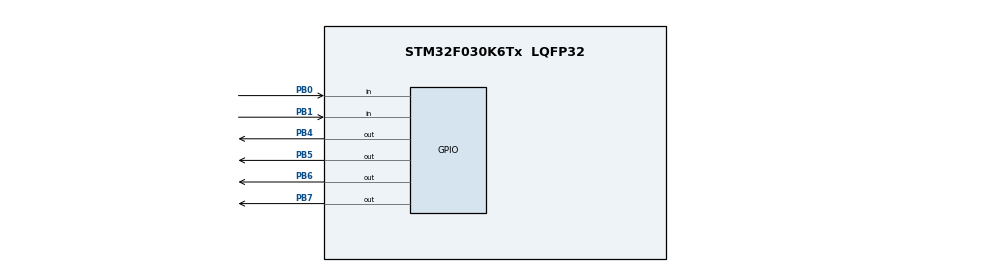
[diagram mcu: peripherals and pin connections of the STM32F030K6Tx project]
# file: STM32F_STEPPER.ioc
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Mcu.Family=STM32F0
Mcu.Name=STM32F030K6Tx
Mcu.Package=LQFP32
PB0.GPIO_PuPd=GPIO_PULLUP
PB0.Signal=GPIO_Input
PB1.GPIO_PuPd=GPIO_PULLUP
PB1.Signal=GPIO_Input
PB4.Signal=GPIO_Output
PB5.Signal=GPIO_Output
PB6.Signal=GPIO_Output
PB7.Signal=GPIO_Output
ProjectManager.HeapSize=0x200
ProjectManager.StackSize=0x400
ProjectManager.TargetToolchain=STM32CubeIDE
board=custom

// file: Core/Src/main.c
/* USER CODE BEGIN Header */
/**
 * 2022-05-14
 * Created by : bonusoid
 * Stepper Motor Control
  ******************************************************************************
  * @file           : main.c
  * @brief          : Main program body
  ******************************************************************************
  * @attention
  *
  * Copyright (c) 2022 STMicroelectronics.
  * All rights reserved.
  *
  * This software is licensed under terms that can be found in the LICENSE file
  * in the root directory of this software component.
  * If no LICENSE file comes with this software, it is provided AS-IS.
  *
  ******************************************************************************
  */
/* USER CODE END Header */
#include "main.h"

/* USER CODE BEGIN PD */
#define MOTIO	GPIOB //Stepper Motor GPIO Port
#define MOTP1	4	  //Stepper Motor Pin 1
#define BTNIO	GPIOB      //Button GPIO Port
#define BTNCW	GPIO_PIN_0 //Button for Clockwise
#define BTNCCW	GPIO_PIN_1 //Button for Counter-Clockwise
/* USER CODE END PD */

/* USER CODE BEGIN PV */
//STEP SEQUENCE
unsigned char stepcw[4] = {0b1010,0b1001,0b0101,0b0110};  //Clockwise
unsigned char stepccw[4] = {0b0101,0b1001,0b1010,0b0110}; //Counter-Clockwise
/* USER CODE END PV */

void SystemClock_Config(void);
static void MX_GPIO_Init(void);
/* USER CODE BEGIN PFP */
void setstep(unsigned char st); //Update rotor step
/* USER CODE END PFP */

int main(void)
{
  /* USER CODE BEGIN 1 */
  unsigned char sti; //Step increment
  /* USER CODE END 1 */

  /* MCU Configuration--------------------------------------------------------*/

  /* Reset of all peripherals, Initializes the Flash interface and the Systick. */
  HAL_Init();

  /* Configure the system clock */
  SystemClock_Config();

  /* Initialize all configured peripherals */
  MX_GPIO_Init();

  /* Infinite loop */
  while (1)
  {
	  if((HAL_GPIO_ReadPin(BTNIO, BTNCW))==GPIO_PIN_RESET) //If CW Button is pressed (Active Low)
	  {
	  		for(sti=0;sti<4;sti++)
	  		{
	  			setstep(stepcw[sti]); //Run CW sequence
	  			HAL_Delay(10);
	  		}
	  }
	  else if((HAL_GPIO_ReadPin(BTNIO, BTNCCW))==GPIO_PIN_RESET) //If CCW Button is pressed (Active Low)
	  {
	  		for(sti=0;sti<4;sti++)
	  		{
	  			setstep(stepccw[sti]); //Run CCW sequence
	  			HAL_Delay(10);
	  		}
	  }
	  else
	  {
	  		MOTIO->ODR = 0x00;
	  }
  }
}

void SystemClock_Config(void)
{
  RCC_OscInitTypeDef RCC_OscInitStruct = {0};
  RCC_ClkInitTypeDef RCC_ClkInitStruct = {0};

  /** Initializes the RCC Oscillators according to the specified parameters
  * in the RCC_OscInitTypeDef structure.
  */
  RCC_OscInitStruct.OscillatorType = RCC_OSCILLATORTYPE_HSI;
  RCC_OscInitStruct.HSIState = RCC_HSI_ON;
  RCC_OscInitStruct.HSICalibrationValue = RCC_HSICALIBRATION_DEFAULT;
  RCC_OscInitStruct.PLL.PLLState = RCC_PLL_NONE;
  if (HAL_RCC_OscConfig(&RCC_OscInitStruct) != HAL_OK)
  {
    Error_Handler();
  }
  /** Initializes the CPU, AHB and APB buses clocks
  */
  RCC_ClkInitStruct.ClockType = RCC_CLOCKTYPE_HCLK|RCC_CLOCKTYPE_SYSCLK
                              |RCC_CLOCKTYPE_PCLK1;
  RCC_ClkInitStruct.SYSCLKSource = RCC_SYSCLKSOURCE_HSI;
  RCC_ClkInitStruct.AHBCLKDivider = RCC_SYSCLK_DIV1;
  RCC_ClkInitStruct.APB1CLKDivider = RCC_HCLK_DIV1;

  if (HAL_RCC_ClockConfig(&RCC_ClkInitStruct, FLASH_LATENCY_0) != HAL_OK)
  {
    Error_Handler();
  }
}

static void MX_GPIO_Init(void)
{
  GPIO_InitTypeDef GPIO_InitStruct = {0};

  /* GPIO Ports Clock Enable */
  __HAL_RCC_GPIOB_CLK_ENABLE();

  /*Configure GPIO pin Output Level */
  HAL_GPIO_WritePin(GPIOB, GPIO_PIN_4|GPIO_PIN_5|GPIO_PIN_6|GPIO_PIN_7, GPIO_PIN_RESET);

  //Configure Pins for Buttons
  /*Configure GPIO pins : PB0 PB1 */
  GPIO_InitStruct.Pin = GPIO_PIN_0|GPIO_PIN_1;
  GPIO_InitStruct.Mode = GPIO_MODE_INPUT;
  GPIO_InitStruct.Pull = GPIO_PULLUP; //Use internal pull-up
  HAL_GPIO_Init(GPIOB, &GPIO_InitStruct);

  //Configure Pins for Stepper Motor
  /*Configure GPIO pins : PB4 PB5 PB6 PB7 */
  GPIO_InitStruct.Pin = GPIO_PIN_4|GPIO_PIN_5|GPIO_PIN_6|GPIO_PIN_7;
  GPIO_InitStruct.Mode = GPIO_MODE_OUTPUT_PP;
  GPIO_InitStruct.Pull = GPIO_NOPULL;
  GPIO_InitStruct.Speed = GPIO_SPEED_FREQ_LOW;
  HAL_GPIO_Init(GPIOB, &GPIO_InitStruct);

}

/* USER CODE BEGIN 4 */
void setstep(unsigned char st)
{
	MOTIO->ODR = st<<MOTP1; //Update step
}
/* USER CODE END 4 */

void Error_Handler(void)
{
  __disable_irq();
  while (1)
  {
  }
}
